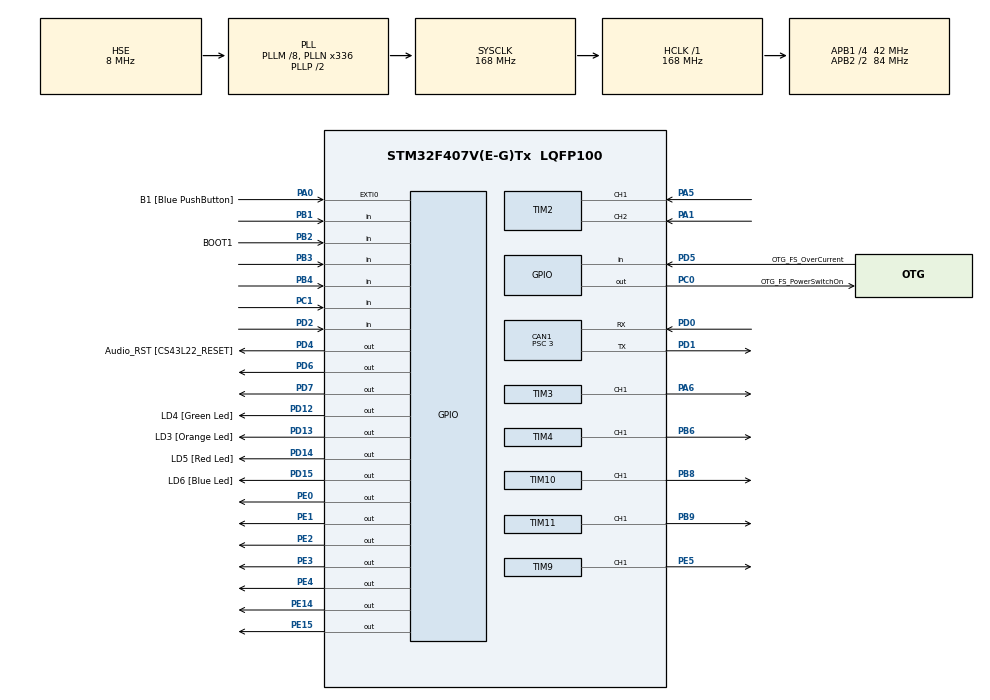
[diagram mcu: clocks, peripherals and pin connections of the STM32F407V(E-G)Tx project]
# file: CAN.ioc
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CAN1.BS1=CAN_BS1_10TQ
CAN1.BS2=CAN_BS2_3TQ
CAN1.CalculateBaudRate=1000000
CAN1.CalculateTimeBit=1000
CAN1.CalculateTimeQuantum=71.42857142857143
CAN1.Prescaler=3
Mcu.Family=STM32F4
Mcu.Name=STM32F407V(E-G)Tx
Mcu.Package=LQFP100
NVIC.CAN1_RX0_IRQn=true\:0\:0\:false\:false\:true\:true\:true\:true
NVIC.PriorityGroup=NVIC_PRIORITYGROUP_0
NVIC.TIM1_BRK_TIM9_IRQn=true\:0\:0\:false\:false\:true\:true\:true\:true
NVIC.TIM1_TRG_COM_TIM11_IRQn=true\:0\:0\:false\:false\:true\:true\:true\:true
NVIC.TIM1_UP_TIM10_IRQn=true\:0\:0\:false\:false\:true\:true\:true\:true
NVIC.TIM3_IRQn=true\:0\:0\:false\:false\:true\:true\:true\:true
NVIC.TIM4_IRQn=true\:0\:0\:false\:false\:true\:true\:true\:true
NVIC.TIM8_BRK_TIM12_IRQn=true\:0\:0\:false\:false\:true\:true\:true\:true
NVIC.TIM8_UP_TIM13_IRQn=true\:0\:0\:false\:false\:true\:true\:true\:true
PA0-WKUP.GPIO_Label=B1 [Blue PushButton]
PA0-WKUP.GPIO_ModeDefaultEXTI=GPIO_MODE_EVT_RISING
PA0-WKUP.GPIO_PuPd=GPIO_NOPULL
PA0-WKUP.Signal=GPXTI0
PA1.Signal=S_TIM2_CH2
PA13.GPIO_Label=SWDIO
PA13.Mode=Serial_Wire
PA13.Signal=SYS_JTMS-SWDIO
PA14.GPIO_Label=SWCLK
PA14.Mode=Serial_Wire
PA14.Signal=SYS_JTCK-SWCLK
PA5.Signal=S_TIM2_CH1_ETR
PA6.Signal=S_TIM3_CH1
PB1.Signal=GPIO_Input
PB2.GPIO_Label=BOOT1
PB2.GPIO_Mode=GPIO_MODE_INPUT
PB2.GPIO_PuPd=GPIO_NOPULL
PB2.Signal=GPIO_Input
PB3.Signal=GPIO_Input
PB4.Signal=GPIO_Input
PB6.Signal=S_TIM4_CH1
PB8.Signal=S_TIM10_CH1
PB9.Signal=S_TIM11_CH1
PC0.GPIO_Label=OTG_FS_PowerSwitchOn
PC0.GPIO_PuPd=GPIO_NOPULL
PC0.GPIO_Speed=GPIO_SPEED_FREQ_LOW
PC0.PinState=GPIO_PIN_SET
PC0.Signal=GPIO_Output
PC1.GPIO_PuPd=GPIO_NOPULL
PC1.Signal=GPIO_Input
PC14-OSC32_IN.GPIO_Label=PC14-OSC32_IN
PC14-OSC32_IN.Mode=LSE-External-Oscillator
PC14-OSC32_IN.Signal=RCC_OSC32_IN
PC15-OSC32_OUT.GPIO_Label=PC15-OSC32_OUT
PC15-OSC32_OUT.Mode=LSE-External-Oscillator
PC15-OSC32_OUT.Signal=RCC_OSC32_OUT
PD0.Mode=CAN_Activate
PD0.Signal=CAN1_RX
PD1.Mode=CAN_Activate
PD1.Signal=CAN1_TX
PD12.GPIO_Label=LD4 [Green Led]
PD12.GPIO_PuPd=GPIO_NOPULL
PD12.GPIO_Speed=GPIO_SPEED_FREQ_LOW
PD12.Signal=GPIO_Output
PD13.GPIO_Label=LD3 [Orange Led]
PD13.GPIO_PuPd=GPIO_NOPULL
PD13.GPIO_Speed=GPIO_SPEED_FREQ_LOW
PD13.Signal=GPIO_Output
PD14.GPIO_Label=LD5 [Red Led]
PD14.GPIO_PuPd=GPIO_NOPULL
PD14.GPIO_Speed=GPIO_SPEED_FREQ_LOW
PD14.Signal=GPIO_Output
PD15.GPIO_Label=LD6 [Blue Led]
PD15.GPIO_PuPd=GPIO_NOPULL
PD15.GPIO_Speed=GPIO_SPEED_FREQ_LOW
PD15.Signal=GPIO_Output
PD2.Signal=GPIO_Input
PD4.GPIO_Label=Audio_RST [CS43L22_RESET]
PD4.GPIO_PuPd=GPIO_NOPULL
PD4.GPIO_Speed=GPIO_SPEED_FREQ_LOW
PD4.Signal=GPIO_Output
PD5.GPIO_Label=OTG_FS_OverCurrent
PD5.GPIO_Mode=GPIO_MODE_INPUT
PD5.GPIO_PuPd=GPIO_NOPULL
PD5.Signal=GPIO_Input
PD6.Signal=GPIO_Output
PD7.Signal=GPIO_Output
PE0.Signal=GPIO_Output
PE1.Signal=GPIO_Output
PE14.Signal=GPIO_Output
PE15.Signal=GPIO_Output
PE2.Signal=GPIO_Output
PE3.Signal=GPIO_Output
PE4.Signal=GPIO_Output
PE5.Signal=S_TIM9_CH1
PH0-OSC_IN.GPIO_Label=PH0-OSC_IN
PH0-OSC_IN.Mode=HSE-External-Oscillator
PH0-OSC_IN.Signal=RCC_OSC_IN
PH1-OSC_OUT.GPIO_Label=PH1-OSC_OUT
PH1-OSC_OUT.Mode=HSE-External-Oscillator
PH1-OSC_OUT.Signal=RCC_OSC_OUT
ProjectManager.HeapSize=0x200
ProjectManager.StackSize=0x400
ProjectManager.TargetToolchain=STM32CubeIDE
RCC.48MHZClocksFreq_Value=48000000
RCC.AHBFreq_Value=168000000
RCC.APB1CLKDivider=RCC_HCLK_DIV4
RCC.APB1Freq_Value=42000000
RCC.APB1TimFreq_Value=84000000
RCC.APB2CLKDivider=RCC_HCLK_DIV2
RCC.APB2Freq_Value=84000000
RCC.APB2TimFreq_Value=168000000
RCC.CortexFreq_Value=168000000
RCC.HCLKFreq_Value=168000000
RCC.HSE_VALUE=8000000
RCC.HSI_VALUE=16000000
RCC.PLLM=8
RCC.PLLN=336
RCC.PLLQ=7
RCC.PLLSourceVirtual=RCC_PLLSOURCE_HSE
RCC.SYSCLKFreq_VALUE=168000000
RCC.SYSCLKSource=RCC_SYSCLKSOURCE_PLLCLK
RCC.VCOOutputFreq_Value=336000000
SH.S_TIM10_CH1.0=TIM10_CH1,Output Compare1 CH1
SH.S_TIM11_CH1.0=TIM11_CH1,Output Compare1 CH1
SH.S_TIM2_CH1_ETR.0=TIM2_CH1,Encoder_Interface
SH.S_TIM2_CH2.0=TIM2_CH2,Encoder_Interface
SH.S_TIM3_CH1.0=TIM3_CH1,Output Compare1 CH1
SH.S_TIM4_CH1.0=TIM4_CH1,Output Compare1 CH1
SH.S_TIM9_CH1.0=TIM9_CH1,Output Compare1 CH1
TIM10.Channel=TIM_CHANNEL_1
TIM10.OCMode_1=TIM_OCMODE_TOGGLE
TIM11.Channel=TIM_CHANNEL_1
TIM11.OCMode_1=TIM_OCMODE_TOGGLE
TIM12.Channel-Output\ Compare1\ No\ Output=TIM_CHANNEL_1
TIM12.Pulse-Output\ Compare1\ No\ Output=65000
TIM13.Channel=TIM_CHANNEL_1
TIM2.AutoReloadPreload=TIM_AUTORELOAD_PRELOAD_ENABLE
TIM2.EncoderMode=TIM_ENCODERMODE_TI12
TIM2.IC1Filter=0
TIM2.IC2Filter=0
TIM3.Channel-Output\ Compare1\ CH1=TIM_CHANNEL_1
TIM3.OCMode_1=TIM_OCMODE_TOGGLE
TIM4.Channel-Output\ Compare1\ CH1=TIM_CHANNEL_1
TIM4.OCMode_1=TIM_OCMODE_TOGGLE
TIM9.Channel-Output\ Compare1\ CH1=TIM_CHANNEL_1
TIM9.OCMode_1=TIM_OCMODE_TOGGLE
TIM9.OCPolarity_1=TIM_OCPOLARITY_HIGH
TIM9.Pulse-Output\ Compare1\ CH1=0
VP_TIM10_VS_ClockSourceINT.Mode=Enable_Timer
VP_TIM11_VS_ClockSourceINT.Mode=Enable_Timer
VP_TIM12_VS_no_output1.Mode=Output Compare1 No Output
VP_TIM13_VS_ClockSourceINT.Mode=Enable_Timer
VP_TIM13_VS_no_output1.Mode=Output Compare1 No Output
VP_TIM3_VS_ClockSourceINT.Mode=Internal
VP_TIM4_VS_ClockSourceINT.Mode=Internal
board=STM32F407G-DISC1

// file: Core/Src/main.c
/* USER CODE BEGIN Header */
/**
  ******************************************************************************
  * @file           : main.c
  * @brief          : Main program body
  ******************************************************************************
  * @attention
  *
  * Copyright (c) 2022 STMicroelectronics.
  * All rights reserved.
  *
  * This software is licensed under terms that can be found in the LICENSE file
  * in the root directory of this software component.
  * If no LICENSE file comes with this software, it is provided AS-IS.
  *
  ******************************************************************************
  */
/* USER CODE END Header */
#include "main.h"

/* USER CODE BEGIN Includes */
//#include "structs.h"
#include "C:/Users/Samuel/source/repos/motion_planner_oop/oop_test/microcontroller_data_set.h"
#include "macros.h"
#include "structs.h"
/* USER CODE END Includes */

CAN_HandleTypeDef hcan1;

TIM_HandleTypeDef htim2;
TIM_HandleTypeDef htim3;
TIM_HandleTypeDef htim4;
TIM_HandleTypeDef htim9;
TIM_HandleTypeDef htim10;
TIM_HandleTypeDef htim11;
TIM_HandleTypeDef htim12;
TIM_HandleTypeDef htim13;

void SystemClock_Config(void);
static void MX_GPIO_Init(void);
static void MX_CAN1_Init(void);
static void MX_TIM9_Init(void);
static void MX_TIM10_Init(void);
static void MX_TIM11_Init(void);
static void MX_TIM12_Init(void);
static void MX_TIM13_Init(void);
static void MX_TIM3_Init(void);
static void MX_TIM2_Init(void);
static void MX_TIM4_Init(void);
/* USER CODE BEGIN PFP */
static void start_first_move();
static void setup();
static void go_to_home_position(int split);
static void start_program();
static void move_axis(int32_t increment,int32_t direction,char axis);
static void check_command();
void send_position_message(uint32_t number_1,uint32_t number_2,uint32_t identifier);
void send_data();//thats all kinds of data for displaying standpoint, codeblock, all kinds of things
//thats done via uart because its not time and savety critical
static int get_mailbox();
static int is_mailbox_empty(int mailbox_nr);
static void measure_tool();
static void homing_cycle();

/* USER CODE END PFP */

/* USER CODE BEGIN 0 */

extern void request_receiving_data();

CAN_TxHeaderTypeDef tx_header;
//CAN_TxHeaderTypeDef rx_header;

volatile struct microcontroller_data_set fifo_buffer[FIFO_BUFFER_SIZE];
volatile uint32_t fifo_write_ctr=0;
volatile uint32_t fifo_read_ctr=FIFO_BUFFER_SIZE;

volatile struct axis_data x_data;
volatile struct axis_data y_data;
volatile struct axis_data z_data;
volatile struct axis_data b_data;
volatile struct axis_data c_data;
volatile uint32_t n_line_data;

volatile uint32_t flags_global_mc=0;

volatile uint32_t acceleration = 0;

//those are only for the manual controll
volatile uint32_t commands=0;
volatile uint16_t timer_speed=SPEED_1;
volatile uint32_t increment=20;

volatile uint32_t motor_start_status=0;
volatile uint32_t motor_x_direction=0;
volatile uint32_t motor_y_direction=0;
volatile uint32_t motor_z_direction=0;
volatile uint32_t motor_b_direction=0;
volatile uint32_t motor_c_direction=0;

//uint8_t tx_data[8];

//uint32_t tx_mailbox;

//uint32_t ctr=0;

volatile int32_t x_target=0;
volatile int32_t y_target=0;
volatile int32_t z_target=0;
volatile int32_t b_target=0;
volatile int32_t c_target=0;
volatile int32_t y_target_left=0;
volatile int32_t y_target_right=0;

volatile int32_t x_standpoint=0;
volatile int32_t y_standpoint=0;
volatile int32_t z_standpoint=0;
volatile int32_t b_standpoint=0;
volatile int32_t c_standpoint=0;
volatile int32_t y_standpoint_left=0;
volatile int32_t y_standpoint_right=0;

volatile uint32_t gcode_line_number=0;

volatile int32_t x_standpoint_previous=0;
volatile int32_t y_standpoint_previous=0;
volatile int32_t z_standpoint_previous=0;
volatile int32_t b_standpoint_previous=0;
volatile int32_t c_standpoint_previous=0;

/* USER CODE END 0 */

int main(void)
{

  /* MCU Configuration--------------------------------------------------------*/

  /* Reset of all peripherals, Initializes the Flash interface and the Systick. */
  HAL_Init();

  /* Configure the system clock */
  SystemClock_Config();

  /* Initialize all configured peripherals */
  MX_GPIO_Init();
  MX_CAN1_Init();
  MX_TIM9_Init();
  MX_TIM10_Init();
  MX_TIM11_Init();
  MX_TIM12_Init();
  MX_TIM13_Init();
  MX_TIM3_Init();
  MX_TIM2_Init();
  MX_TIM4_Init();
  /* USER CODE BEGIN 2 */
  HAL_CAN_Start(&hcan1);
  HAL_CAN_ActivateNotification(&hcan1,CAN_IT_RX_FIFO0_MSG_PENDING);

  // I changed this on 28.09.2023
  //commands&=~START_PROGRAM;
  //flags_global_mc|=MACHINE_HOMED;

  setup();

  /* USER CODE END 2 */

  /* Infinite loop */
  /* USER CODE BEGIN WHILE */
  while (1)
  {
	check_command();
    /* USER CODE END WHILE */

  }
}

void SystemClock_Config(void)
{
  RCC_OscInitTypeDef RCC_OscInitStruct = {0};
  RCC_ClkInitTypeDef RCC_ClkInitStruct = {0};

  /** Configure the main internal regulator output voltage
  */
  __HAL_RCC_PWR_CLK_ENABLE();
  __HAL_PWR_VOLTAGESCALING_CONFIG(PWR_REGULATOR_VOLTAGE_SCALE1);

  /** Initializes the RCC Oscillators according to the specified parameters
  * in the RCC_OscInitTypeDef structure.
  */
  RCC_OscInitStruct.OscillatorType = RCC_OSCILLATORTYPE_HSE;
  RCC_OscInitStruct.HSEState = RCC_HSE_ON;
  RCC_OscInitStruct.PLL.PLLState = RCC_PLL_ON;
  RCC_OscInitStruct.PLL.PLLSource = RCC_PLLSOURCE_HSE;
  RCC_OscInitStruct.PLL.PLLM = 8;
  RCC_OscInitStruct.PLL.PLLN = 336;
  RCC_OscInitStruct.PLL.PLLP = RCC_PLLP_DIV2;
  RCC_OscInitStruct.PLL.PLLQ = 7;
  if (HAL_RCC_OscConfig(&RCC_OscInitStruct) != HAL_OK)
  {
    Error_Handler();
  }

  /** Initializes the CPU, AHB and APB buses clocks
  */
  RCC_ClkInitStruct.ClockType = RCC_CLOCKTYPE_HCLK|RCC_CLOCKTYPE_SYSCLK
                              |RCC_CLOCKTYPE_PCLK1|RCC_CLOCKTYPE_PCLK2;
  RCC_ClkInitStruct.SYSCLKSource = RCC_SYSCLKSOURCE_PLLCLK;
  RCC_ClkInitStruct.AHBCLKDivider = RCC_SYSCLK_DIV1;
  RCC_ClkInitStruct.APB1CLKDivider = RCC_HCLK_DIV4;
  RCC_ClkInitStruct.APB2CLKDivider = RCC_HCLK_DIV2;

  if (HAL_RCC_ClockConfig(&RCC_ClkInitStruct, FLASH_LATENCY_5) != HAL_OK)
  {
    Error_Handler();
  }
}

static void MX_CAN1_Init(void)
{

  hcan1.Instance = CAN1;
  hcan1.Init.Prescaler = 3;
  hcan1.Init.Mode = CAN_MODE_NORMAL;
  hcan1.Init.SyncJumpWidth = CAN_SJW_1TQ;
  hcan1.Init.TimeSeg1 = CAN_BS1_10TQ;
  hcan1.Init.TimeSeg2 = CAN_BS2_3TQ;
  hcan1.Init.TimeTriggeredMode = DISABLE;
  hcan1.Init.AutoBusOff = DISABLE;
  hcan1.Init.AutoWakeUp = DISABLE;
  hcan1.Init.AutoRetransmission = DISABLE;
  hcan1.Init.ReceiveFifoLocked = DISABLE;
  hcan1.Init.TransmitFifoPriority = DISABLE;
  if (HAL_CAN_Init(&hcan1) != HAL_OK)
  {
    Error_Handler();
  }
  /* USER CODE BEGIN CAN1_Init 2 */
  CAN_FilterTypeDef canfilterconfig;
  canfilterconfig.FilterActivation=CAN_FILTER_ENABLE;
  canfilterconfig.FilterBank=10;
  canfilterconfig.FilterFIFOAssignment=CAN_RX_FIFO0;
  canfilterconfig.FilterIdHigh=0;
  canfilterconfig.FilterIdLow=0;
  canfilterconfig.FilterMaskIdHigh=0;
  canfilterconfig.FilterMaskIdLow=0;
  canfilterconfig.FilterMode=CAN_FILTERMODE_IDMASK;
  canfilterconfig.FilterScale=CAN_FILTERSCALE_32BIT;
  canfilterconfig.SlaveStartFilterBank=0;

  HAL_CAN_ConfigFilter(&hcan1,&canfilterconfig);
  /* USER CODE END CAN1_Init 2 */

}

static void MX_TIM2_Init(void)
{

  TIM_Encoder_InitTypeDef sConfig = {0};
  TIM_MasterConfigTypeDef sMasterConfig = {0};

  htim2.Instance = TIM2;
  htim2.Init.Prescaler = 0;
  htim2.Init.CounterMode = TIM_COUNTERMODE_UP;
  htim2.Init.Period = 4294967295;
  htim2.Init.ClockDivision = TIM_CLOCKDIVISION_DIV1;
  htim2.Init.AutoReloadPreload = TIM_AUTORELOAD_PRELOAD_ENABLE;
  sConfig.EncoderMode = TIM_ENCODERMODE_TI12;
  sConfig.IC1Polarity = TIM_ICPOLARITY_RISING;
  sConfig.IC1Selection = TIM_ICSELECTION_DIRECTTI;
  sConfig.IC1Prescaler = TIM_ICPSC_DIV1;
  sConfig.IC1Filter = 0;
  sConfig.IC2Polarity = TIM_ICPOLARITY_RISING;
  sConfig.IC2Selection = TIM_ICSELECTION_DIRECTTI;
  sConfig.IC2Prescaler = TIM_ICPSC_DIV1;
  sConfig.IC2Filter = 0;
  if (HAL_TIM_Encoder_Init(&htim2, &sConfig) != HAL_OK)
  {
    Error_Handler();
  }
  sMasterConfig.MasterOutputTrigger = TIM_TRGO_RESET;
  sMasterConfig.MasterSlaveMode = TIM_MASTERSLAVEMODE_DISABLE;
  if (HAL_TIMEx_MasterConfigSynchronization(&htim2, &sMasterConfig) != HAL_OK)
  {
    Error_Handler();
  }

}

static void MX_TIM3_Init(void)
{

  TIM_ClockConfigTypeDef sClockSourceConfig = {0};
  TIM_MasterConfigTypeDef sMasterConfig = {0};
  TIM_OC_InitTypeDef sConfigOC = {0};

  htim3.Instance = TIM3;
  htim3.Init.Prescaler = 0;
  htim3.Init.CounterMode = TIM_COUNTERMODE_UP;
  htim3.Init.Period = 65535;
  htim3.Init.ClockDivision = TIM_CLOCKDIVISION_DIV1;
  htim3.Init.AutoReloadPreload = TIM_AUTORELOAD_PRELOAD_DISABLE;
  if (HAL_TIM_Base_Init(&htim3) != HAL_OK)
  {
    Error_Handler();
  }
  sClockSourceConfig.ClockSource = TIM_CLOCKSOURCE_INTERNAL;
  if (HAL_TIM_ConfigClockSource(&htim3, &sClockSourceConfig) != HAL_OK)
  {
    Error_Handler();
  }
  if (HAL_TIM_OC_Init(&htim3) != HAL_OK)
  {
    Error_Handler();
  }
  sMasterConfig.MasterOutputTrigger = TIM_TRGO_RESET;
  sMasterConfig.MasterSlaveMode = TIM_MASTERSLAVEMODE_DISABLE;
  if (HAL_TIMEx_MasterConfigSynchronization(&htim3, &sMasterConfig) != HAL_OK)
  {
    Error_Handler();
  }
  sConfigOC.OCMode = TIM_OCMODE_TOGGLE;
  sConfigOC.Pulse = 0;
  sConfigOC.OCPolarity = TIM_OCPOLARITY_HIGH;
  sConfigOC.OCFastMode = TIM_OCFAST_DISABLE;
  if (HAL_TIM_OC_ConfigChannel(&htim3, &sConfigOC, TIM_CHANNEL_1) != HAL_OK)
  {
    Error_Handler();
  }
  /* USER CODE BEGIN TIM3_Init 2 */
  TIM3->ARR=60000;
  TIM3->PSC=10;

  /* USER CODE END TIM3_Init 2 */
  HAL_TIM_MspPostInit(&htim3);

}

static void MX_TIM4_Init(void)
{

  TIM_ClockConfigTypeDef sClockSourceConfig = {0};
  TIM_MasterConfigTypeDef sMasterConfig = {0};
  TIM_OC_InitTypeDef sConfigOC = {0};

  htim4.Instance = TIM4;
  htim4.Init.Prescaler = 0;
  htim4.Init.CounterMode = TIM_COUNTERMODE_UP;
  htim4.Init.Period = 65535;
  htim4.Init.ClockDivision = TIM_CLOCKDIVISION_DIV1;
  htim4.Init.AutoReloadPreload = TIM_AUTORELOAD_PRELOAD_DISABLE;
  if (HAL_TIM_Base_Init(&htim4) != HAL_OK)
  {
    Error_Handler();
  }
  sClockSourceConfig.ClockSource = TIM_CLOCKSOURCE_INTERNAL;
  if (HAL_TIM_ConfigClockSource(&htim4, &sClockSourceConfig) != HAL_OK)
  {
    Error_Handler();
  }
  if (HAL_TIM_OC_Init(&htim4) != HAL_OK)
  {
    Error_Handler();
  }
  sMasterConfig.MasterOutputTrigger = TIM_TRGO_RESET;
  sMasterConfig.MasterSlaveMode = TIM_MASTERSLAVEMODE_DISABLE;
  if (HAL_TIMEx_MasterConfigSynchronization(&htim4, &sMasterConfig) != HAL_OK)
  {
    Error_Handler();
  }
  sConfigOC.OCMode = TIM_OCMODE_TOGGLE;
  sConfigOC.Pulse = 0;
  sConfigOC.OCPolarity = TIM_OCPOLARITY_HIGH;
  sConfigOC.OCFastMode = TIM_OCFAST_DISABLE;
  if (HAL_TIM_OC_ConfigChannel(&htim4, &sConfigOC, TIM_CHANNEL_1) != HAL_OK)
  {
    Error_Handler();
  }
  HAL_TIM_MspPostInit(&htim4);

}

static void MX_TIM9_Init(void)
{

  TIM_OC_InitTypeDef sConfigOC = {0};

  htim9.Instance = TIM9;
  htim9.Init.Prescaler = 0;
  htim9.Init.CounterMode = TIM_COUNTERMODE_UP;
  htim9.Init.Period = 65535;
  htim9.Init.ClockDivision = TIM_CLOCKDIVISION_DIV1;
  htim9.Init.AutoReloadPreload = TIM_AUTORELOAD_PRELOAD_DISABLE;
  if (HAL_TIM_OC_Init(&htim9) != HAL_OK)
  {
    Error_Handler();
  }
  sConfigOC.OCMode = TIM_OCMODE_TOGGLE;
  sConfigOC.Pulse = 0;
  sConfigOC.OCPolarity = TIM_OCPOLARITY_HIGH;
  sConfigOC.OCFastMode = TIM_OCFAST_DISABLE;
  if (HAL_TIM_OC_ConfigChannel(&htim9, &sConfigOC, TIM_CHANNEL_1) != HAL_OK)
  {
    Error_Handler();
  }
  HAL_TIM_MspPostInit(&htim9);

}

static void MX_TIM10_Init(void)
{

  TIM_OC_InitTypeDef sConfigOC = {0};

  htim10.Instance = TIM10;
  htim10.Init.Prescaler = 0;
  htim10.Init.CounterMode = TIM_COUNTERMODE_UP;
  htim10.Init.Period = 65535;
  htim10.Init.ClockDivision = TIM_CLOCKDIVISION_DIV1;
  htim10.Init.AutoReloadPreload = TIM_AUTORELOAD_PRELOAD_DISABLE;
  if (HAL_TIM_Base_Init(&htim10) != HAL_OK)
  {
    Error_Handler();
  }
  if (HAL_TIM_OC_Init(&htim10) != HAL_OK)
  {
    Error_Handler();
  }
  sConfigOC.OCMode = TIM_OCMODE_TOGGLE;
  sConfigOC.Pulse = 0;
  sConfigOC.OCPolarity = TIM_OCPOLARITY_HIGH;
  sConfigOC.OCFastMode = TIM_OCFAST_DISABLE;
  if (HAL_TIM_OC_ConfigChannel(&htim10, &sConfigOC, TIM_CHANNEL_1) != HAL_OK)
  {
    Error_Handler();
  }
  /* USER CODE BEGIN TIM10_Init 2 */
  TIM10->ARR=60000;
  TIM10->PSC=5;
  /* USER CODE END TIM10_Init 2 */
  HAL_TIM_MspPostInit(&htim10);

}

static void MX_TIM11_Init(void)
{

  TIM_OC_InitTypeDef sConfigOC = {0};

  htim11.Instance = TIM11;
  htim11.Init.Prescaler = 0;
  htim11.Init.CounterMode = TIM_COUNTERMODE_UP;
  htim11.Init.Period = 65535;
  htim11.Init.ClockDivision = TIM_CLOCKDIVISION_DIV1;
  htim11.Init.AutoReloadPreload = TIM_AUTORELOAD_PRELOAD_DISABLE;
  if (HAL_TIM_Base_Init(&htim11) != HAL_OK)
  {
    Error_Handler();
  }
  if (HAL_TIM_OC_Init(&htim11) != HAL_OK)
  {
    Error_Handler();
  }
  sConfigOC.OCMode = TIM_OCMODE_TOGGLE;
  sConfigOC.Pulse = 0;
  sConfigOC.OCPolarity = TIM_OCPOLARITY_HIGH;
  sConfigOC.OCFastMode = TIM_OCFAST_DISABLE;
  if (HAL_TIM_OC_ConfigChannel(&htim11, &sConfigOC, TIM_CHANNEL_1) != HAL_OK)
  {
    Error_Handler();
  }
  /* USER CODE BEGIN TIM11_Init 2 */
  TIM11->ARR=60000;
  TIM11->PSC=3;
  /* USER CODE END TIM11_Init 2 */
  HAL_TIM_MspPostInit(&htim11);

}

static void MX_TIM12_Init(void)
{

  TIM_OC_InitTypeDef sConfigOC = {0};

  htim12.Instance = TIM12;
  htim12.Init.Prescaler = 0;
  htim12.Init.CounterMode = TIM_COUNTERMODE_UP;
  htim12.Init.Period = 65535;
  htim12.Init.ClockDivision = TIM_CLOCKDIVISION_DIV1;
  htim12.Init.AutoReloadPreload = TIM_AUTORELOAD_PRELOAD_DISABLE;
  if (HAL_TIM_OC_Init(&htim12) != HAL_OK)
  {
    Error_Handler();
  }
  sConfigOC.OCMode = TIM_OCMODE_TIMING;
  sConfigOC.Pulse = 65000;
  sConfigOC.OCPolarity = TIM_OCPOLARITY_HIGH;
  sConfigOC.OCFastMode = TIM_OCFAST_DISABLE;
  if (HAL_TIM_OC_ConfigChannel(&htim12, &sConfigOC, TIM_CHANNEL_1) != HAL_OK)
  {
    Error_Handler();
  }

}

static void MX_TIM13_Init(void)
{

  TIM_OC_InitTypeDef sConfigOC = {0};

  htim13.Instance = TIM13;
  htim13.Init.Prescaler = 0;
  htim13.Init.CounterMode = TIM_COUNTERMODE_UP;
  htim13.Init.Period = 65535;
  htim13.Init.ClockDivision = TIM_CLOCKDIVISION_DIV1;
  htim13.Init.AutoReloadPreload = TIM_AUTORELOAD_PRELOAD_DISABLE;
  if (HAL_TIM_Base_Init(&htim13) != HAL_OK)
  {
    Error_Handler();
  }
  if (HAL_TIM_OC_Init(&htim13) != HAL_OK)
  {
    Error_Handler();
  }
  sConfigOC.OCMode = TIM_OCMODE_TIMING;
  sConfigOC.Pulse = 0;
  sConfigOC.OCPolarity = TIM_OCPOLARITY_HIGH;
  sConfigOC.OCFastMode = TIM_OCFAST_DISABLE;
  if (HAL_TIM_OC_ConfigChannel(&htim13, &sConfigOC, TIM_CHANNEL_1) != HAL_OK)
  {
    Error_Handler();
  }

}

static void MX_GPIO_Init(void)
{
  GPIO_InitTypeDef GPIO_InitStruct = {0};

  /* GPIO Ports Clock Enable */
  __HAL_RCC_GPIOE_CLK_ENABLE();
  __HAL_RCC_GPIOC_CLK_ENABLE();
  __HAL_RCC_GPIOH_CLK_ENABLE();
  __HAL_RCC_GPIOA_CLK_ENABLE();
  __HAL_RCC_GPIOB_CLK_ENABLE();
  __HAL_RCC_GPIOD_CLK_ENABLE();

  /*Configure GPIO pin Output Level */
  HAL_GPIO_WritePin(GPIOE, GPIO_PIN_2|GPIO_PIN_3|GPIO_PIN_4|GPIO_PIN_0|GPIO_PIN_14|GPIO_PIN_15
                          |GPIO_PIN_1, GPIO_PIN_RESET);

  /*Configure GPIO pin Output Level */
  HAL_GPIO_WritePin(OTG_FS_PowerSwitchOn_GPIO_Port, OTG_FS_PowerSwitchOn_Pin, GPIO_PIN_SET);

  /*Configure GPIO pin Output Level */
  HAL_GPIO_WritePin(GPIOD, LD4_Pin|LD3_Pin|LD5_Pin|LD6_Pin
                          |Audio_RST_Pin, GPIO_PIN_RESET);

  /*Configure GPIO pins : PE2 PE3 PE4 PE0
                           PE1 */
  GPIO_InitStruct.Pin = GPIO_PIN_2|GPIO_PIN_3|GPIO_PIN_4|GPIO_PIN_0|GPIO_PIN_14|GPIO_PIN_15
                          |GPIO_PIN_1;
  GPIO_InitStruct.Mode = GPIO_MODE_OUTPUT_PP;
  GPIO_InitStruct.Pull = GPIO_NOPULL;
  GPIO_InitStruct.Speed = GPIO_SPEED_FREQ_LOW;
  HAL_GPIO_Init(GPIOE, &GPIO_InitStruct);

  /*Configure GPIO pin : OTG_FS_PowerSwitchOn_Pin */
  GPIO_InitStruct.Pin = OTG_FS_PowerSwitchOn_Pin;
  GPIO_InitStruct.Mode = GPIO_MODE_OUTPUT_PP;
  GPIO_InitStruct.Pull = GPIO_NOPULL;
  GPIO_InitStruct.Speed = GPIO_SPEED_FREQ_LOW;
  HAL_GPIO_Init(OTG_FS_PowerSwitchOn_GPIO_Port, &GPIO_InitStruct);

  /*Configure GPIO pin : PC1 */
  GPIO_InitStruct.Pin = GPIO_PIN_1;
  GPIO_InitStruct.Mode = GPIO_MODE_INPUT;
  GPIO_InitStruct.Pull = GPIO_NOPULL;
  HAL_GPIO_Init(GPIOC, &GPIO_InitStruct);

  /*Configure GPIO pin : B1_Pin */
  GPIO_InitStruct.Pin = B1_Pin;
  GPIO_InitStruct.Mode = GPIO_MODE_EVT_RISING;
  GPIO_InitStruct.Pull = GPIO_NOPULL;
  HAL_GPIO_Init(B1_GPIO_Port, &GPIO_InitStruct);

  /*Configure GPIO pins : PB1 BOOT1_Pin PB3 PB4 */
  GPIO_InitStruct.Pin = GPIO_PIN_1|BOOT1_Pin|GPIO_PIN_3|GPIO_PIN_2|GPIO_PIN_10;

  GPIO_InitStruct.Mode = GPIO_MODE_INPUT;
  GPIO_InitStruct.Pull = GPIO_NOPULL;
  HAL_GPIO_Init(GPIOB, &GPIO_InitStruct);

/*
  GPIO_InitStruct.Pin = GPIO_PIN_10|GPIO_PIN_11;
  GPIO_InitStruct.Mode = GPIO_MODE_INPUT;
  GPIO_InitStruct.Pull = GPIO_NOPULL;
  HAL_GPIO_Init(GPIOB, &GPIO_InitStruct);
*/
  /*Configure GPIO pins : LD4_Pin LD3_Pin LD5_Pin LD6_Pin
                           Audio_RST_Pin */
  GPIO_InitStruct.Pin = LD4_Pin|LD3_Pin|LD5_Pin|LD6_Pin
                          |Audio_RST_Pin;
  GPIO_InitStruct.Mode = GPIO_MODE_OUTPUT_PP;
  GPIO_InitStruct.Pull = GPIO_NOPULL;
  GPIO_InitStruct.Speed = GPIO_SPEED_FREQ_LOW;
  HAL_GPIO_Init(GPIOD, &GPIO_InitStruct);

  /*Configure GPIO pins : PD2 OTG_FS_OverCurrent_Pin */
  GPIO_InitStruct.Pin = GPIO_PIN_2|GPIO_PIN_6|GPIO_PIN_7|OTG_FS_OverCurrent_Pin;
  GPIO_InitStruct.Mode = GPIO_MODE_INPUT;
  GPIO_InitStruct.Pull = GPIO_NOPULL;
  HAL_GPIO_Init(GPIOD, &GPIO_InitStruct);

}

/* USER CODE BEGIN 4 */

static void start_first_move()
{
	//thats to reinitialize the timers
	//because before the GPIO of the Compare pins
	//where otherwise used
	MX_TIM9_Init();
	MX_TIM10_Init();
	MX_TIM11_Init();
	MX_TIM12_Init();
	MX_TIM3_Init();
	MX_TIM4_Init();
	commands&=~START_PROGRAM_COMMAND;
	flags_global_mc&=~FIRST_MOVE_IN_PROCESS;
	flags_global_mc|=PROGRAM_RUNNING;
	flags_global_mc&=~BUFFER_FULL;
	//thats the timer to start everything
	init_interrupt_enable();
	init_compare_enable();
	init_timer_start();
	//start position timer
	//I think this is not neccesary anymore,
	//this was to send position data to computer,
	//but this is obsolete I think
	/*
	position_timer_compare_enable();
	position_timer_start();
	*/
	return;
}

static void setup()
{
	HAL_TIM_Encoder_Start(&htim2,TIM_CHANNEL_ALL);
	//TIM2->CR1=1;

	flags_global_mc|=WRITE_CTR_UNDER_READ_CTR;
	flags_global_mc|=FIRST_MOVE;
	//thats if we don't have endswitches...
	//flags_global_mc|=MACHINE_HOMED;

	x_interrupt_enable();
	y_interrupt_enable();
	z_interrupt_enable();
	b_interrupt_enable();
	c_interrupt_enable();
	manual_interrupt_enable();
	//position_timer_interrupt_enable();

	//I have to figure out why that is so important
	tx_header.DLC=8;
	tx_header.IDE=CAN_ID_STD;
	tx_header.RTR=CAN_RTR_DATA;
	CAN1->sTxMailBox->TDTR=8;
}

static void check_command()
{
	if(!commands)
		return;

	if(commands&RESET_MICROCONTROLLER_COMMAND)
		NVIC_SystemReset();

	//POSITION STANDPOINT REQUESTS
	if(commands&X_POSITION_REQUEST_COMMAND){
		uint32_t input_nr=(uint32_t)x_standpoint;
		send_position_message(input_nr,0,CAN_ID_GET_X_POSITION_ANSWER); //from where the standpoint is should be considered!!
		commands&=~X_POSITION_REQUEST_COMMAND;
		return;
	}
	if(commands&Y_POSITION_REQUEST_COMMAND){
		uint32_t input_nr=(uint32_t)y_standpoint;
		send_position_message(input_nr,0,CAN_ID_GET_Y_POSITION_ANSWER);
		commands&=~Y_POSITION_REQUEST_COMMAND;
		return;
	}
	if(commands&Z_POSITION_REQUEST_COMMAND){
		uint32_t input_nr=(uint32_t)z_standpoint;
		send_position_message(input_nr,0,CAN_ID_GET_Z_POSITION_ANSWER);
		commands&=~Z_POSITION_REQUEST_COMMAND;
		return;
	}
	/*
	if(commands&B_POSITION_REQUEST_FLAG){
		uint32_t input_nr=(uint32_t)b_standpoint;
		send_position_message(input_nr,0,CAN_ID_B_POSITION_ANSWER);
		commands&=~B_POSITION_REQUEST_FLAG;

		return;
	}
	if(commands&C_POSITION_REQUEST_FLAG){
		uint32_t input_nr=(uint32_t)c_standpoint;
		send_position_message(input_nr,0,CAN_ID_C_POSITION_ANSWER);
		commands&=~C_POSITION_REQUEST_FLAG;

		return;
	}
	*/

	if(!NO_ACTIVE_MOVE)	//that can also be switched on when a programm is runnung
		return;

	else if(commands&HOMING_CYCLE_COMMAND){
		homing_cycle();			//thats hardware goes to hardwareswitches
		return;
	}
	else if(commands&HOMING_CYCLE_SPLIT_COMMAND){
		homing_cycle();			//thats hardware goes to hardwareswitches
		return;
	}

	//that has to be done from the home_position after the machine was homed
	if(commands&MEASURE_WCS_TOOL_FLAG_COMMAND){
		measure_tool();
		return;
	}
	if(commands&MEASURE_ACTUAL_TOOL_FLAG_COMMAND){
		measure_tool();
		return;
	}

	//POSITION MOVE_REQUESTS
	else if(commands&MOVE_X_POSITIVE_COMMAND){
		move_axis(increment,POSITIVE,'x');
		return;
	}
	else if(commands&MOVE_X_NEGATIVE_COMMAND){
		move_axis(increment,NEGATIVE,'x');
		return;
	}
	else if(commands&MOVE_Y_POSITIVE_COMMAND){
		move_axis(increment,POSITIVE,'y');
		return;
	}
	else if(commands&MOVE_Y_NEGATIVE_COMMAND){
		move_axis(increment,NEGATIVE,'y');
		return;
	}
	else if(commands&MOVE_Z_POSITIVE_COMMAND){
		move_axis(increment,POSITIVE,'z');
		return;
	}
	else if(commands&MOVE_Z_NEGATIVE_COMMAND){
		move_axis(increment,NEGATIVE,'z');
		return;
	}
	else if(commands&MOVE_B_POSITIVE_COMMAND){
		move_axis(increment,POSITIVE,'b');
		return;
	}
	else if(commands&MOVE_B_NEGATIVE_COMMAND){
		move_axis(increment,NEGATIVE,'b');
		return;
	}
	else if(commands&MOVE_C_POSITIVE_COMMAND){
		move_axis(increment,POSITIVE,'c');
		return;
	}
	else if(commands&MOVE_C_NEGATIVE_COMMAND){
		move_axis(increment,NEGATIVE,'c');
		return;
	}
	else if(commands&MOVE_Y_LEFT_POS_COMMAND){
		move_axis(increment,POSITIVE,'l');
		return;
	}
	else if(commands&MOVE_Y_LEFT_NEG_COMMAND){
		move_axis(increment,NEGATIVE,'l');
		return;
	}
	else if(commands&MOVE_Y_RIGHT_POS_COMMAND){
		move_axis(increment,POSITIVE,'r');
		return;
	}
	else if(commands&MOVE_Y_RIGHT_NEG_COMMAND){
		move_axis(increment,NEGATIVE,'r');
		return;
	}

	//HOME REQUESTS
	if(commands&GO_TO_HOME_COMMAND){
		go_to_home_position(0); //thats software, just goes back to targetxyz 0
		return;
	}
	if(commands&GO_TO_HOME_SPLIT_COMMAND){
		go_to_home_position(1); //thats software, just goes back to targetxyz 0
		return;
	}

	//PROGRAM START REQUEST

	else if(commands&START_PROGRAM_COMMAND){
		if(!(flags_global_mc&BUFFER_FILLING_IN_PROGRESS))
			start_program();
		if(flags_global_mc&BUFFER_FULL)
			start_first_move();
		return;
	}

	return;
}

static void move_axis(int32_t increment,int32_t direction,char axis)
{
	if(!NO_ACTIVE_MOVE)
		return;
	//delete all requests
	commands&=	~MOVE_X_POSITIVE_COMMAND&~MOVE_X_NEGATIVE_COMMAND&
				~MOVE_Y_POSITIVE_COMMAND&~MOVE_Y_NEGATIVE_COMMAND&
				~MOVE_Z_POSITIVE_COMMAND&~MOVE_Z_NEGATIVE_COMMAND&
				~MOVE_B_POSITIVE_COMMAND&~MOVE_B_NEGATIVE_COMMAND&
				~MOVE_C_POSITIVE_COMMAND&~MOVE_C_NEGATIVE_COMMAND&
				~MOVE_Y_LEFT_POS_COMMAND&~MOVE_Y_LEFT_NEG_COMMAND&
				~MOVE_Y_RIGHT_POS_COMMAND&~MOVE_Y_RIGHT_NEG_COMMAND
				;

	if(axis=='c'||axis=='b')
		increment= INCREMENT_3;

	if(!direction)
		increment*=-1;

	switch(axis){
		case 'x':	flags_global_mc|=X_MANUAL_MOVE;
					if(increment)
						x_target+=increment;
					else
						x_target=0;
					motor_x_direction=direction;
					if(direction){
						SET_X_AXIS_POSITIVE_DIRECTION();
					}
					else
						SET_X_AXIS_NEGATIVE_DIRECTION();
					break;

		case 'y':	flags_global_mc|=Y_MANUAL_MOVE;
					if(increment)
						y_target+=increment;
					else
						y_target=0;
					motor_y_direction=direction;
					if(direction){
						SET_Y_AXIS_POSITIVE_DIRECTION();
					}
					else
						SET_Y_AXIS_NEGATIVE_DIRECTION();
					break;

		case 'z':	flags_global_mc|=Z_MANUAL_MOVE;
					if(increment)
						z_target+=increment;
					else
						z_target=0;
					motor_z_direction=direction;
					if(direction){
						SET_Z_AXIS_POSITIVE_DIRECTION();
					}
					else
						SET_Z_AXIS_NEGATIVE_DIRECTION();
					break;
		case 'b':
					flags_global_mc|=B_MANUAL_MOVE;
					if(increment)
						b_target+=increment;
					else
						b_target=0;
					motor_b_direction=direction;
					if(direction){
						SET_B_AXIS_POSITIVE_DIRECTION();
					}
					else
						SET_B_AXIS_NEGATIVE_DIRECTION();
					break;
		case 'c':

					flags_global_mc|=C_MANUAL_MOVE;
					if(increment)
						c_target+=increment;
					else
						c_target=0;
					motor_c_direction=direction;
					if(direction){
						SET_C_AXIS_POSITIVE_DIRECTION();
					}
					else
						SET_C_AXIS_NEGATIVE_DIRECTION();
					break;
		case 'l':	flags_global_mc|=Y_MANUAL_MOVE_LEFT;
					if(increment)
						y_target_left+=increment;
					else
						y_target_left=0;
					motor_y_direction=direction;
					if(direction){
						SET_Y_AXIS_POSITIVE_DIRECTION();
					}
					else
						SET_Y_AXIS_NEGATIVE_DIRECTION();
					break;
		case 'r':	flags_global_mc|=Y_MANUAL_MOVE_RIGHT;
					if(increment)
						y_target_right+=increment;
					else
						y_target_right=0;
					motor_y_direction=direction;
					if(direction){
						SET_Y_AXIS_POSITIVE_DIRECTION();
					}
					else
						SET_Y_AXIS_NEGATIVE_DIRECTION();
					break;

		default:	return;
	}

	//setup for xaxis
	GPIO_InitTypeDef gpio_init_1;
	gpio_init_1.Pin = GPIO_PIN_5;
	gpio_init_1.Mode = GPIO_MODE_OUTPUT_PP;
	gpio_init_1.Pull = GPIO_NOPULL;
	gpio_init_1.Speed = GPIO_SPEED_FREQ_LOW;
	HAL_GPIO_Init(GPIOE, &gpio_init_1);

	//setup for yaxis
	GPIO_InitTypeDef gpio_init_2;
	gpio_init_2.Pin = GPIO_PIN_8;
	gpio_init_2.Mode = GPIO_MODE_OUTPUT_PP;
	gpio_init_2.Pull = GPIO_NOPULL;
	gpio_init_2.Speed = GPIO_SPEED_FREQ_LOW;
	HAL_GPIO_Init(GPIOB, &gpio_init_2);

	//setup for zaxis
	GPIO_InitTypeDef gpio_init_3;
	gpio_init_3.Pin = GPIO_PIN_9;
	gpio_init_3.Mode = GPIO_MODE_OUTPUT_PP;
	gpio_init_3.Pull = GPIO_NOPULL;
	gpio_init_3.Speed = GPIO_SPEED_FREQ_LOW;
	HAL_GPIO_Init(GPIOB, &gpio_init_3);

	//setup for baxis
	GPIO_InitTypeDef gpio_init_4;
	gpio_init_4.Pin = GPIO_PIN_6;
	gpio_init_4.Mode = GPIO_MODE_OUTPUT_PP;
	gpio_init_4.Pull = GPIO_NOPULL;
	gpio_init_4.Speed = GPIO_SPEED_FREQ_LOW;
	HAL_GPIO_Init(GPIOA, &gpio_init_4);

	//setup for caxis
	GPIO_InitTypeDef gpio_init_5;
	gpio_init_5.Pin = GPIO_PIN_6;
	gpio_init_5.Mode = GPIO_MODE_OUTPUT_PP;
	gpio_init_5.Pull = GPIO_NOPULL;
	gpio_init_5.Speed = GPIO_SPEED_FREQ_LOW;
	HAL_GPIO_Init(GPIOB, &gpio_init_5);

	//setup for y l axis
	/*
	GPIO_InitTypeDef gpio_init_6;
	gpio_init_6.Pin = GPIO_PIN_10;
	gpio_init_6.Mode = GPIO_MODE_OUTPUT_PP;
	gpio_init_6.Pull = GPIO_NOPULL;
	gpio_init_6.Speed = GPIO_SPEED_FREQ_LOW;
	HAL_GPIO_Init(GPIOB, &gpio_init_6);
*/
	//setup for y r axis
	//this has to be switched off for not seperate steering...
	//in other words, for seperate the 11 has to be initialized
	if(flags_global_mc&Y_MANUAL_MOVE_RIGHT){
		GPIO_InitTypeDef gpio_init_7;
		gpio_init_7.Pin = GPIO_PIN_11;
		gpio_init_7.Mode = GPIO_MODE_OUTPUT_PP;
		gpio_init_7.Pull = GPIO_NOPULL;
		gpio_init_7.Speed = GPIO_SPEED_FREQ_LOW;
		HAL_GPIO_Init(GPIOB, &gpio_init_7);
	}

	if(axis=='b'||axis=='c'){
		TIM13->PSC=400;

	}
	else
		TIM13->PSC=1;
	TIM13->ARR=timer_speed;
	//x_compare_enable();
	manual_compare_enable();
	manual_timer_start();

	return;
}

//is machine homed, is machine at 0, is there no manual move going on

static void start_program()
{
	if(MACHINE_READY_FOR_PROGRAM){
		flags_global_mc|=BUFFER_FILLING_IN_PROGRESS;
		request_receiving_data();
	}

	return;
}

//this should be not neccesary anymore because to go every time to the end switches would be much better

void go_to_home_position(int split)
{
	//first home the z axis, else you could drive into the workpiece

	if(z_standpoint>0)
		move_axis(MOVE_TO_ZERO,NEGATIVE,'z');
	else if(z_standpoint<0)
		move_axis(MOVE_TO_ZERO,POSITIVE,'z');
	else if(x_standpoint>0)
		move_axis(MOVE_TO_ZERO,NEGATIVE,'x');
	else if(x_standpoint<0)
		move_axis(MOVE_TO_ZERO,POSITIVE,'x');
	else if(split == 1){
		if(y_standpoint_left>0)
			move_axis(MOVE_TO_ZERO,NEGATIVE,'l');
		if(y_standpoint_left<0)
			move_axis(MOVE_TO_ZERO,POSITIVE,'l');
		if(y_standpoint_right>0)
			move_axis(MOVE_TO_ZERO,NEGATIVE,'r');
		if(y_standpoint_right<0)
			move_axis(MOVE_TO_ZERO,POSITIVE,'r');
	}
	else if(split == 0){
		if(y_standpoint>0)
			move_axis(MOVE_TO_ZERO,NEGATIVE,'y');
		if(y_standpoint<0)
			move_axis(MOVE_TO_ZERO,POSITIVE,'y');
		else{
			commands&=~GO_TO_HOME_COMMAND;
			send_position_message(0,0,CAN_ID_MACHINE_HOME);
		}
	}

	return;
}

static void homing_cycle(){
//first home the z axis, else you could drive into the workpiece
	if(!(flags_global_mc&Z_HOMED))
		move_axis(1000000,POSITIVE,'z');
	else if(!(flags_global_mc&X_HOMED))
		move_axis(1000000,NEGATIVE,'x');
	else if(!(flags_global_mc&Y_HOMED)){
		for(int i = 0; i < 1000; i++)
			;
		if(commands&HOMING_CYCLE_SPLIT_COMMAND){
			if(!(flags_global_mc&Y_HOMED_LEFT))
				move_axis(1000000,NEGATIVE,'l');
			if(!(flags_global_mc&Y_HOMED_RIGHT))
				move_axis(1000000,NEGATIVE,'r');
		}
		else if(commands&HOMING_CYCLE_COMMAND)
			move_axis(1000000,NEGATIVE,'y');
	}
	else{

		flags_global_mc&=~Z_HOMED;
		flags_global_mc&=~X_HOMED;
		flags_global_mc&=~Y_HOMED;
		flags_global_mc|=MACHINE_HOMED;
		//send_position_message(0,0,CAN_ID_MACHINE_HOME);
		//that would be not good because the home position would mean we are at the endswitches,
		//witch means we are not allowed to move, that would mean if we would start anything from there,
		//we would  need again an exeption...
		/*
		x_standpoint=0;
		y_standpoint=0;
		z_standpoint=0;
		*/
		//There has to be a figured out a good place to move after the homing cycle so that the axis are not
		//at the endswitches anymore
		x_standpoint=-6400;//it woudl move a bit to the right in case of go to home
		z_standpoint=6400;
		if(commands&HOMING_CYCLE_COMMAND)
			y_standpoint=-6400;//this has to change for axis direction change...
		if(commands&HOMING_CYCLE_SPLIT_COMMAND){
		y_standpoint_left = -6400;
		y_standpoint_right = -6400;
		}
		//after that go to home
		if(commands&HOMING_CYCLE_COMMAND)
			commands|=GO_TO_HOME_COMMAND;//move all axis to 0
		if(commands&HOMING_CYCLE_SPLIT_COMMAND)
			commands|=GO_TO_HOME_SPLIT_COMMAND;//move all axis to 0
		commands&=~HOMING_CYCLE_COMMAND;
		commands&=~HOMING_CYCLE_SPLIT_COMMAND;
	}
	return;
}
//homeposition means all axis are at 0, that is slightly besides the endswitches, in order that they are not pressed
#define MACHINE_AT_HOME_POSITION (x_standpoint==0&&y_standpoint==0&&z_standpoint==0)

static void measure_tool()
{
	//if Machine is homed, and if its at xyz 0;
	//else first home or at least go xyz to 0 then measure the tool
	//
	if((flags_global_mc&MACHINE_HOMED)&&MACHINE_AT_HOME_POSITION)
		move_axis(1000000,NEGATIVE,'z');
	else if(flags_global_mc&MEASURED_TOOL){
		uint32_t input_nr=(uint32_t)z_standpoint;//if this number is -1(should not happen, than the value of the input_nr will be 0xffffffff) thats a problem, its oviously not because in the gui there is still the right value...
		if(commands & MEASURE_WCS_TOOL_FLAG_COMMAND)
			send_position_message(input_nr,0,MEASURE_WCS_TOOL_ANSWER_ID);\
		if(commands & MEASURE_ACTUAL_TOOL_FLAG_COMMAND)
			send_position_message(input_nr,0,MEASURE_ACTUAL_TOOL_ANSWER_ID);
		flags_global_mc&=~MEASURED_TOOL;
		commands&=~MEASURE_WCS_TOOL_FLAG_COMMAND;
		commands&=~MEASURE_ACTUAL_TOOL_FLAG_COMMAND;
		timer_speed=SPEED_1;
		commands|=GO_TO_HOME_COMMAND;//move all axis to 0
	}

	return;

}

//the number is allways an int32_t, the identifier is 11 bit, means max2048
void send_position_message(uint32_t number_1,uint32_t number_2,uint32_t identifier)
{
        int mailbox_nr=0;
        mailbox_nr=get_mailbox();       //returns number of empty mailboxor at least lowest priority pending mailbox

        if(is_mailbox_empty(mailbox_nr)){       //in case of an request for new data this whould be forced
                CAN1->sTxMailBox[mailbox_nr].TDTR=(8<<CAN_TDT0R_DLC_Pos); //because its an int32_t... 4 bytes
                CAN1->sTxMailBox[mailbox_nr].TDLR=number_1;
                CAN1->sTxMailBox[mailbox_nr].TDHR=number_2;
                CAN1->sTxMailBox[mailbox_nr].TIR=0;
                CAN1->sTxMailBox[mailbox_nr].TIR|=identifier;
                CAN1->sTxMailBox[mailbox_nr].TIR|=CAN_TI0R_TXRQ;        //that means start to transmit the message
        }
        return;
}

static int get_mailbox()
{
        int ret=0;
        ret=CAN1->TSR&CAN_TSR_CODE;
        return ret;
}

static int is_mailbox_empty(int mailbox_nr)
{
        int ret=0;
        ret=CAN1->TSR&(1<<(CAN_TSR_TME_Pos+mailbox_nr));
        return ret;
}

/* USER CODE END 4 */

void Error_Handler(void)
{
  __disable_irq();
  while (1)
  {
  }
}
